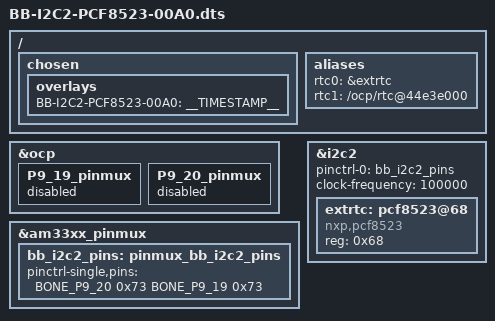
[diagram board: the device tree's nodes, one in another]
/*
 * Copyright (C) 2017 Robert Nelson <robertcnelson@gmail.com>
 *
 * This program is free software; you can redistribute it and/or modify
 * it under the terms of the GNU General Public License version 2 as
 * published by the Free Software Foundation.
 */

/dts-v1/;
/plugin/;

#include <dt-bindings/board/am335x-bbw-bbb-base.h>
#include <dt-bindings/pinctrl/am33xx.h>
#include <dt-bindings/gpio/gpio.h>

/ {
	/*
	 * Helper to show loaded overlays under: /proc/device-tree/chosen/overlays/
	 */
	fragment@0 {
		target-path="/";
		__overlay__ {

			chosen {
				overlays {
					BB-I2C2-PCF8523-00A0 = __TIMESTAMP__;
				};
			};
		};
	};

	/*
	 * Free up the pins used by the cape from the pinmux helpers.
	 */
	fragment@1 {
		target = <&ocp>;
		__overlay__ {
			P9_19_pinmux { status = "disabled"; };	/* i2c2_scl */
			P9_20_pinmux { status = "disabled"; };	/* i2c2_sda */
		};
	};

	fragment@2 {
		target-path="/";
		__overlay__ {
			aliases {
				rtc0 = &extrtc;
				rtc1 = "/ocp/rtc@44e3e000";
			};
		};
	};

	fragment@3 {
		target = <&am33xx_pinmux>;
		__overlay__ {
			bb_i2c2_pins: pinmux_bb_i2c2_pins {
				pinctrl-single,pins = <
					BONE_P9_20 0x73	/* i2c2_sda, SLEWCTRL_SLOW | INPUT_PULLUP | MODE3 */
					BONE_P9_19 0x73	/* i2c2_scl, SLEWCTRL_SLOW | INPUT_PULLUP | MODE3 */
				>;
			};
		};
	};

	fragment@4 {
		target = <&i2c2>;
		__overlay__ {
			status = "okay";
			pinctrl-names = "default";
			pinctrl-0 = <&bb_i2c2_pins>;

			/* this is the configuration part */
			clock-frequency = <100000>;

			#address-cells = <1>;
			#size-cells = <0>;

			extrtc: pcf8523@68 {
				compatible = "nxp,pcf8523";
				reg = <0x68>;
			};
		};
	};
};
